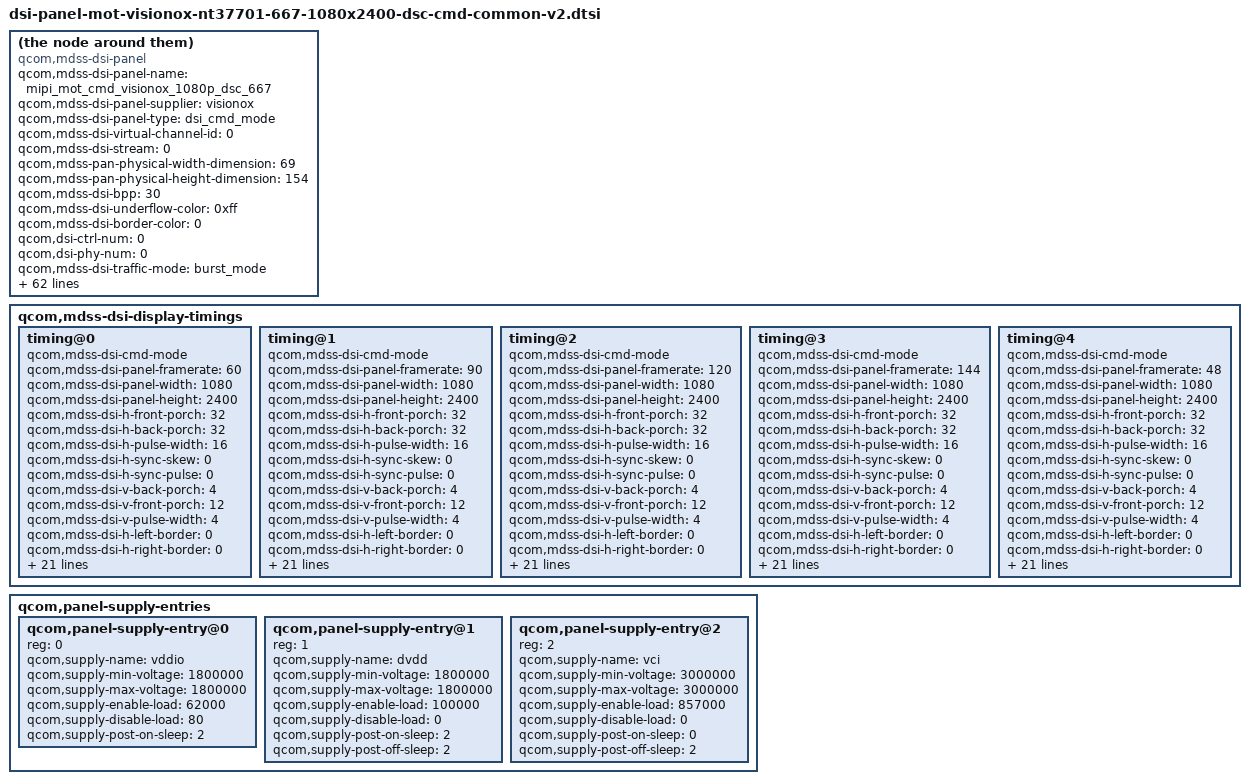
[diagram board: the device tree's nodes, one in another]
/* Copyright (c) 2019-2020, The Linux Foundation. All rights reserved.
 *
 * This program is free software; you can redistribute it and/or modify
 * it under the terms of the GNU General Public License version 2 and
 * only version 2 as published by the Free Software Foundation.
 *
 * This program is distributed in the hope that it will be useful,
 * but WITHOUT ANY WARRANTY; without even the implied warranty of
 * MERCHANTABILITY or FITNESS FOR A PARTICULAR PURPOSE.  See the
 * GNU General Public License for more details.
 */

compatible = "qcom,mdss-dsi-panel";
qcom,mdss-dsi-panel-name = "mipi_mot_cmd_visionox_1080p_dsc_667";
qcom,mdss-dsi-panel-supplier = "visionox";
qcom,mdss-dsi-panel-type = "dsi_cmd_mode";
qcom,mdss-dsi-virtual-channel-id = <0>;
qcom,mdss-dsi-stream = <0>;
qcom,mdss-pan-physical-width-dimension = <69>;
qcom,mdss-pan-physical-height-dimension = <154>;
qcom,mdss-dsi-bpp = <30>;
qcom,mdss-dsi-underflow-color = <0xff>;
qcom,mdss-dsi-border-color = <0>;

qcom,dsi-ctrl-num = <0>;
qcom,dsi-phy-num = <0>;

qcom,mdss-dsi-traffic-mode = "burst_mode";
qcom,mdss-dsi-bllp-eof-power-mode;
qcom,mdss-dsi-bllp-power-mode;
qcom,mdss-dsi-lane-0-state;
qcom,mdss-dsi-lane-1-state;
qcom,mdss-dsi-lane-2-state;
qcom,mdss-dsi-lane-3-state;

qcom,mdss-dsi-dma-trigger = "trigger_sw";
qcom,mdss-dsi-mdp-trigger = "none";
qcom,mdss-dsi-reset-sequence = <0 11>, <1 1>, <0 1>, <1 11>;
qcom,mdss-dsi-lp11-init;
qcom,mdss-dsi-tx-eot-append;
qcom,mdss-dsi-te-pin-select = <1>;
qcom,mdss-dsi-te-dcs-command = <1>;

qcom,mdss-dsi-te-using-te-pin;

//qcom,esd-check-enabled;
qcom,mdss-dsi-panel-status-check-mode = "te_chk_reg_rd";
qcom,mdss-dsi-panel-status-command = [06 01 00 01 00 00 01 0a];
qcom,mdss-dsi-panel-status-command-state = "dsi_lp_mode";
qcom,mdss-dsi-panel-status-value = <0x9c>;
qcom,mdss-dsi-panel-status-read-length = <1>;
//qcom,mdss-dsi-no-panel-on-read-support;

qcom,bklt-dcs-2bytes-enabled;
qcom,mdss-dsi-bl-min-level = <3>;
qcom,mdss-dsi-bl-max-level = <2047>;
qcom,mdss-dsi-bl-default-level = <1024>;
qcom,mdss-brightness-max-level = <2047>;
qcom,mdss-dsi-bl-pmic-control-type = "bl_ctrl_dcs";

qcom,mdss-dsi-hbm-on-command = [
		39 01 00 00 00 00 03 51 0F FF];
qcom,mdss-dsi-hbm-on-command-state = "dsi_lp_mode";
qcom,mdss-dsi-hbm-off-command = [
		39 01 00 00 00 00 03 51 07 FF];
qcom,mdss-dsi-hbm-off-command-state = "dsi_lp_mode";

qcom,mdss-dsi-color-vbt-command = [
                15 01 00 00 00 00 02 55 90];
qcom,mdss-dsi-color-vbt-command-state = "dsi_lp_mode";
qcom,mdss-dsi-color-std-command = [
                15 01 00 00 00 00 02 55 90];
qcom,mdss-dsi-color-std-command-state = "dsi_lp_mode";
qcom,mdss-dsi-color-game-command = [
		15 01 00 00 00 00 02 55 80];
qcom,mdss-dsi-color-game-command-state = "dsi_lp_mode";
qcom,mdss-dsi-color-none-command = [
		15 01 00 00 00 00 02 55 90];
qcom,mdss-dsi-color-none-command-state = "dsi_lp_mode";

qcom,mdss-dsi-dc-on-command = [
		39 01 00 00 00 00 06 F0 55 AA 52 08 00
		15 00 00 00 00 00 02 B2 90
		15 00 00 00 00 00 02 6F 0F
		39 00 00 00 00 00 09 B2 00 30 00 00 00 00 0F FF
		39 00 00 00 00 00 25 B3 00 00 00 00 00 00 00 00 00 00 00 00 00 00 00 00 00 00 00 00 00 00 01 C2 01 C2 03 C0 03 C0 07 FF 07 FF 0F FF
		39 00 00 00 00 00 27 B4 00 0A 00 0A 00 0A 00 0A 00 0A 00 0A 00 0A 00 0A 00 0A 00 0A 00 0A 00 0A 00 0A 00 0A 00 0A 00 0A 00 0A 00 0A 00 0A
		15 00 00 00 00 00 02 6F 2C
		39 00 00 00 00 00 27 B3 00 0A 00 0A 00 0A 00 0A 00 0A 00 0A 00 0A 00 0A 00 0A 00 0A 00 0A 00 0A 00 0A 00 0A 00 0A 00 0A 00 0A 00 0A 00 0A
		15 00 00 00 00 00 02 6F 30
		39 00 00 00 00 00 27 B4 00 0A 00 0A 00 0A 00 0A 00 0A 00 0A 00 0A 00 0A 00 0A 00 0A 00 0A 00 0A 00 0A 00 0A 00 0A 00 0A 00 0A 00 0A 00 0A
		15 00 00 00 00 00 02 6F 56
		39 01 00 00 00 00 27 B4 00 0A 00 0A 00 0A 00 0A 00 0A 00 0A 00 0A 00 0A 00 0A 00 0A 00 0A 00 0A 00 0A 00 0A 00 0A 00 0A 00 0A 00 0A 00 0A

		15 00 00 00 00 00 02 6F AC
		39 00 00 00 00 00 15 B2 00 00 01 40 01 B6 02 0F 02 59 02 99 02 D3 03 07 03 38 03 65
		15 00 00 00 00 00 02 6F C0
		39 00 00 00 00 00 15 B2 03 B8 04 C5 05 98 06 4C 06 EA 07 79 07 FC 08 76 08 E7 09 53
		15 00 00 00 00 00 02 6F D4
		39 00 00 00 00 00 15 B2 09 B9 0A 1A 0A 77 0A D0 0B 26 0B C0 0C 50 0C D9 0D 5B 0D D8
		15 00 00 00 00 00 02 6F E8
		39 00 00 00 00 00 0b B2 0E 50 0E C3 0F 32 0F 9D 0F FF
		15 00 00 00 00 00 02 6F 52
		39 00 00 00 00 00 15 B3 00 01 00 03 00 04 00 06 00 08 00 09 00 0B 00 0D 00 0E 00 12
		15 00 00 00 00 00 02 6F 66
		39 00 00 00 00 00 15 B3 00 1F 00 2C 00 39 00 47 00 54 00 61 00 6E 00 7C 00 89 00 96
		15 00 00 00 00 00 02 6F 7A
		39 00 00 00 00 00 15 B3 00 A3 00 B1 00 BE 00 CB 00 E4 00 FD 01 15 01 2E 01 47 01 60
		15 00 00 00 00 00 02 6F 8E
		39 00 00 00 00 00 09 B3 01 79 01 92 01 AA 01 C2
		39 00 00 00 00 00 06 F0 55 AA 52 08 04
		39 00 00 00 00 00 11 CB 86 02 05 20 4C B8 00 08 00 96 01 C2 03 C0 07 FF
		39 01 00 00 00 00 06 F0 55 AA 52 08 04
		//60HZ
		//R
		15 00 00 00 00 00 02 6F 00
		39 00 00 00 00 00 1a D2 45 4F 2F 1F 1F 36 36 26 26 16 13 40 40 30 20 71 3F 3F 3F 3F 6F 3E 3E 3E 3E
		//G
		15 00 00 00 00 00 02 6F 19
		39 00 00 00 00 00 1a D2 45 4F 2F 1F 1F 36 35 25 25 15 13 40 40 30 20 6F 3E 3E 3E 3E 6D 3D 3D 3D 3D
		//B
		15 00 00 00 00 00 02 6F 32
		39 01 00 00 00 00 1a D2 45 4F 2F 1F 1F 33 36 26 26 16 13 40 40 30 20 70 3E 3E 3E 3E 76 41 3F 31 31
		//120HZ
		//R
		15 00 00 00 00 00 02 6F 00
		39 00 00 00 00 00 1a D4 5F 6F 4F 2F 1F 3F 4F 36 36 26 1F 20 40 30 30 71 3F 3F 3F 3F 6F 3E 3E 3E 3E
		//G
		15 00 00 00 00 00 02 6F 19
		39 00 00 00 00 00 1a D4 5F 6F 4F 2F 1F 3F 4F 35 35 25 1F 20 40 30 30 6F 3E 3E 3E 3E 6D 3D 3D 3D 3D
		//B
		15 00 00 00 00 00 02 6F 32
		39 01 00 00 00 00 1a D4 5F 6F 4F 2F 1F 3F 4F 36 36 26 1F 20 40 30 30 70 3E 3E 3E 3E 76 41 41 41 41
		//144Hz
		//R
		15 00 00 00 00 00 02 6F 00
		39 00 00 00 00 00 1a D9 56 8F 4F 2F 1F 4F 4F 36 36 26 16 50 40 40 20 71 3F 3F 3F 3F 36 3E 3E 3E 3E
		//G
		15 00 00 00 00 00 02 6F 19
		39 00 00 00 00 00 1a D9 56 8F 4F 2F 1F 4F 4F 35 35 25 16 50 40 40 20 6F 3E 3E 3E 3E 36 3D 3D 3D 3D
		//B
		15 01 00 00 00 00 02 6F 32
		39 01 00 00 00 00 1a D9 56 8F 4F 2F 1F 4F 4F 36 36 26 16 50 40 40 20 70 3E 3E 3E 3E 36 41 41 41 41];
qcom,mdss-dsi-dc-on-command-state = "dsi_lp_mode";

qcom,mdss-dsi-dc-off-command = [
		39 01 00 00 00 00 06 F0 55 AA 52 08 00
		15 00 00 00 00 00 02 B2 11
		15 00 00 00 00 00 02 6F 0F
		39 00 00 00 00 00 09 B2 60 30 51 C2 81 C2 0F FF
		39 00 00 00 00 00 25 B3 00 00 00 08 00 08 00 19 00 19 00 32 00 32 00 96 00 96 01 C1 01 C1 01 C2 01 C2 03 C0 03 C0 07 FF 07 FF 0F FF
		//EM_DT_Normal
		39 00 00 00 00 00 27 B4 13 20 13 20 11 10 11 10 11 10 11 10 11 10 11 10 0C E4 0C E4 00 F0 00 F0 00 F0 00 F0 00 F0 00 F0 00 F0 00 F0 00 0A
		//EM_DT_HFR1
		15 00 00 00 00 00 02 6F 2C
		39 00 00 00 00 00 27 B3 0C C0 0C C0 0B 60 0B 60 0B 60 0B 60 0B 60 0B 60 08 98 08 98 00 A0 00 A0 00 A0 00 A0 00 A0 00 A0 00 A0 00 A0 00 0A
		//EM_DT_HFR2
		15 00 00 00 00 00 02 6F 30
		39 00 00 00 00 00 27 B4 09 90 09 90 08 88 08 88 08 88 08 88 08 88 08 88 06 72 06 72 00 78 00 78 00 78 00 78 00 78 00 78 00 78 00 78 00 0A
		//EM_DT_HFR3
		15 00 00 00 00 00 02 6F 56
		39 00 00 00 00 00 27 B4 09 88 09 88 08 7F 08 7F 08 7F 08 7F 08 7F 08 7F 06 6D 06 6D 00 64 00 64 00 64 00 64 00 64 00 64 00 64 00 64 00 0A
		//Demura
		39 00 00 00 00 00 06 F0 55 AA 52 08 04
		39 00 00 00 00 00 11 CB 86 0F 1E 3D 7A B8 00 08 00 96 01 C2 03 C0 07 FF

		39 01 00 00 00 00 06 F0 55 AA 52 08 04
		//60HZ
		//R
		15 00 00 00 00 00 02 6F 00
		39 00 00 00 00 00 1a D2 FF 4F 2F 1F 1F 74 26 26 26 26 73 40 40 40 40 71 3F 3F 3F 3F 6F 3E 3E 3E 3E
		//G
		15 00 00 00 00 00 02 6F 19
		39 00 00 00 00 00 1a D2 FF 4F 2F 1F 1F 86 25 25 25 25 73 40 40 40 40 6F 3E 3E 3E 3E 6D 3D 3D 3D 3D
		//B
		15 00 00 00 00 00 02 6F 32
		39 01 00 00 00 00 1a D2 FF 4F 2F 1F 1F 74 26 26 26 26 73 40 40 40 40 70 3E 3E 3E 3E 76 41 41 41 41
		//120HZ
		//R
		15 00 00 00 00 00 02 6F 00
		39 00 00 00 00 00 1a D4 FF 6F 4F 2F 1F FF 4F 36 36 26 FF 40 40 40 40 71 3F 3F 3F 3F 6F 3E 3E 3E 3E
		//G
		15 00 00 00 00 00 02 6F 19
		39 00 00 00 00 00 1a D4 FF 6F 4F 2F 1F FF 4F 35 35 25 FF 40 40 40 40 6F 3E 3E 3E 3E 6D 3D 3D 3D 3D
		//B
		15 00 00 00 00 00 02 6F 32
		39 01 00 00 00 00 1a D4 FF 6F 4F 2F 1F FF 4F 36 36 26 FF 40 40 40 40 70 3E 3E 3E 3E 76 41 41 41 41
		//144Hz
		//R
		15 00 00 00 00 00 02 6F 00
		39 00 00 00 00 00 1a D9 FF 8F 4F 2F 1F FF 4F 36 36 26 FF 50 40 40 40 71 3F 3F 3F 3F 6F 3E 3E 3E 3E
		//G
		15 00 00 00 00 00 02 6F 19
		39 00 00 00 00 00 1a D9 FF 8F 4F 2F 1F FF 4F 35 35 25 FF 50 40 40 40 6F 3E 3E 3E 3E 6D 3D 3D 3D 3D
		//B
		15 00 00 00 00 00 02 6F 32
		39 01 00 00 00 00 1a D9 FF 8F 4F 2F 1F FF 4F 36 36 26 FF 50 40 40 40 70 3E 3E 3E 3E 76 41 41 41 41];
qcom,mdss-dsi-dc-off-command-state = "dsi_lp_mode";



//qcom,mdss-dsi-acl-on-command = [
//		39 01 00 00 00 00 06 F0 55 AA 52 08 00
//		15 00 00 00 00 00 02 B0 0C
//		15 01 00 00 00 00 02 55 05];
//qcom,mdss-dsi-acl-off-command = [
//		15 01 00 00 00 00 02 55 00];

qcom,mdss-dsi-panel-hbm-is-51cmd;

qcom,mdss-dsi-display-timings {
	timing@0{
		/* 60 FPS */
		qcom,mdss-dsi-cmd-mode;
		qcom,mdss-dsi-panel-framerate = <60>;
		qcom,mdss-dsi-panel-width = <1080>;
		qcom,mdss-dsi-panel-height = <2400>;
		qcom,mdss-dsi-h-front-porch = <32>;
		qcom,mdss-dsi-h-back-porch = <32>;
		qcom,mdss-dsi-h-pulse-width = <16>;
		qcom,mdss-dsi-h-sync-skew = <0>;
		qcom,mdss-dsi-h-sync-pulse = <0>;
		qcom,mdss-dsi-v-back-porch = <4>;
		qcom,mdss-dsi-v-front-porch = <12>;
		qcom,mdss-dsi-v-pulse-width = <4>;
		qcom,mdss-dsi-h-left-border = <0>;
		qcom,mdss-dsi-h-right-border = <0>;
		qcom,mdss-dsi-v-top-border = <0>;
		qcom,mdss-dsi-v-bottom-border = <0>;
		qcom,mdss-dsi-panel-jitter = <0x20 0xa>;
		//qcom,mdss-mdp-transfer-time-us = <15790>;
		//qcom,mdss-dsi-panel-clockrate = <487870000>;
		qcom,mdss-dsi-timing-switch-command = [
			15 01 00 00 10 00 02 2F 01
			15 01 00 00 00 00 02 8B 00
		];
		qcom,mdss-dsi-on-command = [
			39 01 00 00 00 00 06 F0 55 AA 52 08 00
			15 01 00 00 00 00 02 6F 02
			39 01 00 00 00 00 03 EC 81 C2
			39 01 00 00 00 00 06 F0 55 AA 52 08 00
			39 01 00 00 00 00 19 CC 40 54 5A 60 66 6A 6C 6C 68 62 5B 53 4D 48 44 41 40 50 60 70 58 68 74 74
			39 01 00 00 00 00 12 CD 40 40 40 40 40 40 40 40 40 45 49 4C 4B 48 44 41 40
			39 01 00 00 00 00 13 CE 00 40 40 40 40 40 40 40 40 40 40 40 40 40 40 40 40 40
			39 01 00 00 00 00 12 CF 40 40 40 40 40 40 40 40 40 40 40 40 40 40 40 40 40
			39 01 00 00 00 00 07 D0 00 00 FC 74 0C 1D
			39 01 00 00 00 00 2E D1 50 50 50 50 50 50 50 50 50 50 50 50 50 50 50 50 50 50 50 50 50 50 50 50 00 00 00 00 00 00 00 00 00 00 00 00 00 06 0C 03 09 0F 68 88 00
			39 01 00 00 00 00 07 D3 30 52 74 74 50 10
			39 01 00 00 00 00 1A D4 0F 77 74 0F 00 14 0F 18 1F 05 0D 14 03 07 0A A0 75 FA 10 44 12 00 00 80 00
			39 01 00 00 00 00 14 D7 30 40 40 40 40 40 40 40 40 40 40 40 40 40 40 40 40 40 40
			15 01 00 00 00 00 02 55 90
			39 01 00 00 00 00 06 F0 55 AA 52 08 07
			39 01 00 00 00 00 03 c0 01 0f
			39 01 00 00 00 00 06 F0 55 AA 52 08 00
			15 01 00 00 00 00 02 6F 06
			39 01 00 00 00 00 10 B5 4B 1B 00 00 00 44 2D 00 00 00 1B 1B 1B 1B 1B
			39 01 00 00 00 00 05 FF AA 55 A5 80
			15 01 00 00 00 00 02 6F 61
			15 01 00 00 00 00 02 F3 80
			15 01 00 00 00 00 02 03 01
			15 01 00 00 00 00 02 90 01
			39 01 00 00 00 00 13 91 AB 28 00 0C C2 00 03 1C 01 7E 00 0F 08 BB 04 3D 10 F0
			15 01 00 00 00 00 02 2C 00
			15 01 00 00 00 00 02 2F 01
			15 01 00 00 00 00 02 8B 00
			39 01 00 00 00 00 03 51 00 00
			15 01 00 00 00 00 02 53 20
			15 01 00 00 00 00 02 35 00
			39 01 00 00 00 00 05 2A 00 00 04 37
			39 01 00 00 00 00 05 2B 00 00 09 5F
			39 01 00 00 00 00 06 F0 55 AA 52 08 04
			//60HZ
			//R
			15 00 00 00 00 00 02 6F 00
			39 00 00 00 00 00 1a D2 FF 4F 2F 1F 1F 74 26 26 26 26 73 40 40 40 40 71 3F 3F 3F 3F 6F 3E 3E 3E 3E
			//G
			15 00 00 00 00 00 02 6F 19
			39 00 00 00 00 00 1a D2 FF 4F 2F 1F 1F 86 25 25 25 25 73 40 40 40 40 6F 3E 3E 3E 3E 6D 3D 3D 3D 3D
			//B
			15 00 00 00 00 00 02 6F 32
			39 01 00 00 00 00 1a D2 FF 4F 2F 1F 1F 74 26 26 26 26 73 40 40 40 40 70 3E 3E 3E 3E 76 41 41 41 41
			//120HZ
			//R
			15 00 00 00 00 00 02 6F 00
			39 00 00 00 00 00 1a D4 FF 6F 4F 2F 1F FF 4F 36 36 26 FF 40 40 40 40 71 3F 3F 3F 3F 6F 3E 3E 3E 3E
			//G
			15 00 00 00 00 00 02 6F 19
			39 00 00 00 00 00 1a D4 FF 6F 4F 2F 1F FF 4F 35 35 25 FF 40 40 40 40 6F 3E 3E 3E 3E 6D 3D 3D 3D 3D
			//B
			15 00 00 00 00 00 02 6F 32
			39 01 00 00 00 00 1a D4 FF 6F 4F 2F 1F FF 4F 36 36 26 FF 40 40 40 40 70 3E 3E 3E 3E 76 41 41 41 41
			//144Hz
			//R
			15 00 00 00 00 00 02 6F 00
			39 00 00 00 00 00 1a D9 FF 8F 4F 2F 1F FF 4F 36 36 26 FF 50 40 40 40 71 3F 3F 3F 3F 6F 3E 3E 3E 3E
			//G
			15 00 00 00 00 00 02 6F 19
			39 00 00 00 00 00 1a D9 FF 8F 4F 2F 1F FF 4F 35 35 25 FF 50 40 40 40 6F 3E 3E 3E 3E 6D 3D 3D 3D 3D
			//B
			15 00 00 00 00 00 02 6F 32
			39 01 00 00 00 00 1a D9 FF 8F 4F 2F 1F FF 4F 36 36 26 FF 50 40 40 40 70 3E 3E 3E 3E 76 41 41 41 41
			39 01 00 00 00 00 06 F0 55 AA 52 08 00
			39 01 00 00 00 00 07 B3 00 00 00 08 00 08
			39 01 00 00 00 00 06 F0 55 AA 52 08 00
			15 01 00 00 00 00 02 6F 08
			15 01 00 00 00 00 02 C0 50
			15 01 00 00 00 00 02 55 90
			05 01 00 00 78 00 01 11
			05 01 00 00 00 00 01 29];	/* display on */
		qcom,mdss-dsi-off-command = [
			05 01 00 00 00 00 01 28		/* display_off */
			05 01 00 00 78 00 01 10];	/* enter sleep mode */

		qcom,mdss-dsi-on-command-state = "dsi_lp_mode";
		qcom,mdss-dsi-off-command-state = "dsi_lp_mode";
		qcom,mdss-dsi-timing-switch-command-state = "dsi_lp_mode";

		qcom,compression-mode = "dsc";
		qcom,mdss-dsc-version = <0x11>;
		qcom,mdss-dsc-slice-height = <12>;
		qcom,mdss-dsc-slice-width = <1080>;
		qcom,mdss-dsc-slice-per-pkt = <1>;
		qcom,mdss-dsc-bit-per-component = <10>;
		qcom,mdss-dsc-bit-per-pixel = <8>;
		qcom,mdss-dsc-block-prediction-enable;
	};

	timing@1{
		/* 90 FPS */
		qcom,mdss-dsi-cmd-mode;
		qcom,mdss-dsi-panel-framerate = <90>;
		qcom,mdss-dsi-panel-width = <1080>;
		qcom,mdss-dsi-panel-height = <2400>;
		qcom,mdss-dsi-h-front-porch = <32>;
		qcom,mdss-dsi-h-back-porch = <32>;
		qcom,mdss-dsi-h-pulse-width = <16>;
		qcom,mdss-dsi-h-sync-skew = <0>;
		qcom,mdss-dsi-h-sync-pulse = <0>;
		qcom,mdss-dsi-v-back-porch = <4>;
		qcom,mdss-dsi-v-front-porch = <12>;
		qcom,mdss-dsi-v-pulse-width = <4>;
		qcom,mdss-dsi-h-left-border = <0>;
		qcom,mdss-dsi-h-right-border = <0>;
		qcom,mdss-dsi-v-top-border = <0>;
		qcom,mdss-dsi-v-bottom-border = <0>;
		qcom,mdss-dsi-panel-jitter = <0x20 0xa>;
		//qcom,mdss-mdp-transfer-time-us = <10311>;
		//qcom,mdss-dsi-panel-clockrate = <731810000>;
		qcom,mdss-dsi-timing-switch-command = [
			15 01 00 00 0B 00 02 2F 02
			15 01 00 00 00 00 02 8B 00
		];
		qcom,mdss-dsi-on-command = [
			39 01 00 00 00 00 06 F0 55 AA 52 08 00
			15 01 00 00 00 00 02 6F 02
			39 01 00 00 00 00 03 EC 81 C2
			39 01 00 00 00 00 06 F0 55 AA 52 08 00
			39 01 00 00 00 00 19 CC 40 54 5A 60 66 6A 6C 6C 68 62 5B 53 4D 48 44 41 40 50 60 70 58 68 74 74
			39 01 00 00 00 00 12 CD 40 40 40 40 40 40 40 40 40 45 49 4C 4B 48 44 41 40
			39 01 00 00 00 00 13 CE 00 40 40 40 40 40 40 40 40 40 40 40 40 40 40 40 40 40
			39 01 00 00 00 00 12 CF 40 40 40 40 40 40 40 40 40 40 40 40 40 40 40 40 40
			39 01 00 00 00 00 07 D0 00 00 FC 74 0C 1D
			39 01 00 00 00 00 2E D1 50 50 50 50 50 50 50 50 50 50 50 50 50 50 50 50 50 50 50 50 50 50 50 50 00 00 00 00 00 00 00 00 00 00 00 00 00 06 0C 03 09 0F 68 88 00
			39 01 00 00 00 00 07 D3 30 52 74 74 50 10
			39 01 00 00 00 00 1A D4 0F 77 74 0F 00 14 0F 18 1F 05 0D 14 03 07 0A A0 75 FA 10 44 12 00 00 80 00
			39 01 00 00 00 00 14 D7 30 40 40 40 40 40 40 40 40 40 40 40 40 40 40 40 40 40 40
			15 01 00 00 00 00 02 55 90
			39 01 00 00 00 00 06 F0 55 AA 52 08 07
			39 01 00 00 00 00 03 c0 01 0f
			39 01 00 00 00 00 06 F0 55 AA 52 08 00
			15 01 00 00 00 00 02 6F 06
			39 01 00 00 00 00 10 B5 4B 1B 00 00 00 44 2D 00 00 00 1B 1B 1B 1B 1B
			39 01 00 00 00 00 05 FF AA 55 A5 80
			15 01 00 00 00 00 02 6F 61
			15 01 00 00 00 00 02 F3 80
			15 01 00 00 00 00 02 03 01
			15 01 00 00 00 00 02 90 01
			39 01 00 00 00 00 13 91 AB 28 00 0C C2 00 03 1C 01 7E 00 0F 08 BB 04 3D 10 F0
			15 01 00 00 00 00 02 2C 00
			15 01 00 00 00 00 02 2F 02
			15 01 00 00 00 00 02 8B 00
			39 01 00 00 00 00 03 51 00 00
			15 01 00 00 00 00 02 53 20
			15 01 00 00 00 00 02 35 00
			39 01 00 00 00 00 05 2A 00 00 04 37
			39 01 00 00 00 00 05 2B 00 00 09 5F
			39 01 00 00 00 00 06 F0 55 AA 52 08 04
			//60HZ
			//R
			15 00 00 00 00 00 02 6F 00
			39 00 00 00 00 00 1a D2 FF 4F 2F 1F 1F 74 26 26 26 26 73 40 40 40 40 71 3F 3F 3F 3F 6F 3E 3E 3E 3E
			//G
			15 00 00 00 00 00 02 6F 19
			39 00 00 00 00 00 1a D2 FF 4F 2F 1F 1F 86 25 25 25 25 73 40 40 40 40 6F 3E 3E 3E 3E 6D 3D 3D 3D 3D
			//B
			15 00 00 00 00 00 02 6F 32
			39 01 00 00 00 00 1a D2 FF 4F 2F 1F 1F 74 26 26 26 26 73 40 40 40 40 70 3E 3E 3E 3E 76 41 41 41 41
			//120HZ
			//R
			15 00 00 00 00 00 02 6F 00
			39 00 00 00 00 00 1a D4 FF 6F 4F 2F 1F FF 4F 36 36 26 FF 40 40 40 40 71 3F 3F 3F 3F 6F 3E 3E 3E 3E
			//G
			15 00 00 00 00 00 02 6F 19
			39 00 00 00 00 00 1a D4 FF 6F 4F 2F 1F FF 4F 35 35 25 FF 40 40 40 40 6F 3E 3E 3E 3E 6D 3D 3D 3D 3D
			//B
			15 00 00 00 00 00 02 6F 32
			39 01 00 00 00 00 1a D4 FF 6F 4F 2F 1F FF 4F 36 36 26 FF 40 40 40 40 70 3E 3E 3E 3E 76 41 41 41 41
			//144Hz
			//R
			15 00 00 00 00 00 02 6F 00
			39 00 00 00 00 00 1a D9 FF 8F 4F 2F 1F FF 4F 36 36 26 FF 50 40 40 40 71 3F 3F 3F 3F 6F 3E 3E 3E 3E
			//G
			15 00 00 00 00 00 02 6F 19
			39 00 00 00 00 00 1a D9 FF 8F 4F 2F 1F FF 4F 35 35 25 FF 50 40 40 40 6F 3E 3E 3E 3E 6D 3D 3D 3D 3D
			//B
			15 00 00 00 00 00 02 6F 32
			39 01 00 00 00 00 1a D9 FF 8F 4F 2F 1F FF 4F 36 36 26 FF 50 40 40 40 70 3E 3E 3E 3E 76 41 41 41 41
			39 01 00 00 00 00 06 F0 55 AA 52 08 00
			39 01 00 00 00 00 07 B3 00 00 00 08 00 08
			39 01 00 00 00 00 06 F0 55 AA 52 08 00
			15 01 00 00 00 00 02 6F 08
			15 01 00 00 00 00 02 C0 50
			15 01 00 00 00 00 02 55 90
			05 01 00 00 78 00 01 11
			05 01 00 00 00 00 01 29];	/* display on */
		qcom,mdss-dsi-off-command = [
			05 01 00 00 00 00 01 28		/* display_off */
			05 01 00 00 78 00 01 10];	/* enter sleep mode */

		qcom,mdss-dsi-on-command-state = "dsi_lp_mode";
		qcom,mdss-dsi-off-command-state = "dsi_lp_mode";
		qcom,mdss-dsi-timing-switch-command-state = "dsi_lp_mode";

		qcom,compression-mode = "dsc";
		qcom,mdss-dsc-version = <0x11>;
		qcom,mdss-dsc-slice-height = <12>;
		qcom,mdss-dsc-slice-width = <1080>;
		qcom,mdss-dsc-slice-per-pkt = <1>;
		qcom,mdss-dsc-bit-per-component = <10>;
		qcom,mdss-dsc-bit-per-pixel = <8>;
		qcom,mdss-dsc-block-prediction-enable;
	};

	timing@2{
		/* 120 FPS */
		qcom,mdss-dsi-cmd-mode;
		qcom,mdss-dsi-panel-framerate = <120>;
		qcom,mdss-dsi-panel-width = <1080>;
		qcom,mdss-dsi-panel-height = <2400>;
		qcom,mdss-dsi-h-front-porch = <32>;
		qcom,mdss-dsi-h-back-porch = <32>;
		qcom,mdss-dsi-h-pulse-width = <16>;
		qcom,mdss-dsi-h-sync-skew = <0>;
		qcom,mdss-dsi-h-sync-pulse = <0>;
		qcom,mdss-dsi-v-back-porch = <4>;
		qcom,mdss-dsi-v-front-porch = <12>;
		qcom,mdss-dsi-v-pulse-width = <4>;
		qcom,mdss-dsi-h-left-border = <0>;
		qcom,mdss-dsi-h-right-border = <0>;
		qcom,mdss-dsi-v-top-border = <0>;
		qcom,mdss-dsi-v-bottom-border = <0>;
		qcom,mdss-dsi-panel-jitter = <0x20 0xa>;
		//qcom,mdss-mdp-transfer-time-us = <7533>;
		//qcom,mdss-dsi-panel-clockrate = <975740000>;
		qcom,mdss-dsi-timing-switch-command = [
			15 01 00 00 08 00 02 2F 03
			15 01 00 00 00 00 02 8B 00
		];
		qcom,mdss-dsi-on-command = [
			39 01 00 00 00 00 06 F0 55 AA 52 08 00
			15 01 00 00 00 00 02 6F 02
			39 01 00 00 00 00 03 EC 81 C2
			39 01 00 00 00 00 06 F0 55 AA 52 08 00
			39 01 00 00 00 00 19 CC 40 54 5A 60 66 6A 6C 6C 68 62 5B 53 4D 48 44 41 40 50 60 70 58 68 74 74
			39 01 00 00 00 00 12 CD 40 40 40 40 40 40 40 40 40 45 49 4C 4B 48 44 41 40
			39 01 00 00 00 00 13 CE 00 40 40 40 40 40 40 40 40 40 40 40 40 40 40 40 40 40
			39 01 00 00 00 00 12 CF 40 40 40 40 40 40 40 40 40 40 40 40 40 40 40 40 40
			39 01 00 00 00 00 07 D0 00 00 FC 74 0C 1D
			39 01 00 00 00 00 2E D1 50 50 50 50 50 50 50 50 50 50 50 50 50 50 50 50 50 50 50 50 50 50 50 50 00 00 00 00 00 00 00 00 00 00 00 00 00 06 0C 03 09 0F 68 88 00
			39 01 00 00 00 00 07 D3 30 52 74 74 50 10
			39 01 00 00 00 00 1A D4 0F 77 74 0F 00 14 0F 18 1F 05 0D 14 03 07 0A A0 75 FA 10 44 12 00 00 80 00
			39 01 00 00 00 00 14 D7 30 40 40 40 40 40 40 40 40 40 40 40 40 40 40 40 40 40 40
			15 01 00 00 00 00 02 55 90
			39 01 00 00 00 00 06 F0 55 AA 52 08 07
			39 01 00 00 00 00 03 c0 01 0f
			39 01 00 00 00 00 06 F0 55 AA 52 08 00
			15 01 00 00 00 00 02 6F 06
			39 01 00 00 00 00 10 B5 4B 1B 00 00 00 44 2D 00 00 00 1B 1B 1B 1B 1B
			39 01 00 00 00 00 05 FF AA 55 A5 80
			15 01 00 00 00 00 02 6F 61
			15 01 00 00 00 00 02 F3 80
			15 01 00 00 00 00 02 03 01
			15 01 00 00 00 00 02 90 01
			39 01 00 00 00 00 13 91 AB 28 00 0C C2 00 03 1C 01 7E 00 0F 08 BB 04 3D 10 F0
			15 01 00 00 00 00 02 2C 00
			15 01 00 00 00 00 02 2F 03
			15 01 00 00 00 00 02 8B 00
			39 01 00 00 00 00 03 51 00 00
			15 01 00 00 00 00 02 53 20
			15 01 00 00 00 00 02 35 00
			39 01 00 00 00 00 05 2A 00 00 04 37
			39 01 00 00 00 00 05 2B 00 00 09 5F
			39 01 00 00 00 00 06 F0 55 AA 52 08 04
			//60HZ
			//R
			15 00 00 00 00 00 02 6F 00
			39 00 00 00 00 00 1a D2 FF 4F 2F 1F 1F 74 26 26 26 26 73 40 40 40 40 71 3F 3F 3F 3F 6F 3E 3E 3E 3E
			//G
			15 00 00 00 00 00 02 6F 19
			39 00 00 00 00 00 1a D2 FF 4F 2F 1F 1F 86 25 25 25 25 73 40 40 40 40 6F 3E 3E 3E 3E 6D 3D 3D 3D 3D
			//B
			15 00 00 00 00 00 02 6F 32
			39 01 00 00 00 00 1a D2 FF 4F 2F 1F 1F 74 26 26 26 26 73 40 40 40 40 70 3E 3E 3E 3E 76 41 41 41 41
			//120HZ
			//R
			15 00 00 00 00 00 02 6F 00
			39 00 00 00 00 00 1a D4 FF 6F 4F 2F 1F FF 4F 36 36 26 FF 40 40 40 40 71 3F 3F 3F 3F 6F 3E 3E 3E 3E
			//G
			15 00 00 00 00 00 02 6F 19
			39 00 00 00 00 00 1a D4 FF 6F 4F 2F 1F FF 4F 35 35 25 FF 40 40 40 40 6F 3E 3E 3E 3E 6D 3D 3D 3D 3D
			//B
			15 00 00 00 00 00 02 6F 32
			39 01 00 00 00 00 1a D4 FF 6F 4F 2F 1F FF 4F 36 36 26 FF 40 40 40 40 70 3E 3E 3E 3E 76 41 41 41 41
			//144Hz
			//R
			15 00 00 00 00 00 02 6F 00
			39 00 00 00 00 00 1a D9 FF 8F 4F 2F 1F FF 4F 36 36 26 FF 50 40 40 40 71 3F 3F 3F 3F 6F 3E 3E 3E 3E
			//G
			15 00 00 00 00 00 02 6F 19
			39 00 00 00 00 00 1a D9 FF 8F 4F 2F 1F FF 4F 35 35 25 FF 50 40 40 40 6F 3E 3E 3E 3E 6D 3D 3D 3D 3D
			//B
			15 00 00 00 00 00 02 6F 32
			39 01 00 00 00 00 1a D9 FF 8F 4F 2F 1F FF 4F 36 36 26 FF 50 40 40 40 70 3E 3E 3E 3E 76 41 41 41 41
                        39 01 00 00 00 00 06 F0 55 AA 52 08 00
                        39 01 00 00 00 00 07 B3 00 00 00 08 00 08
			39 01 00 00 00 00 06 F0 55 AA 52 08 00
			15 01 00 00 00 00 02 6F 08
			15 01 00 00 00 00 02 C0 50
			15 01 00 00 00 00 02 55 90
			05 01 00 00 78 00 01 11
			05 01 00 00 00 00 01 29];	/* display on */
		qcom,mdss-dsi-off-command = [
			05 01 00 00 00 00 01 28		/* display_off */
			05 01 00 00 78 00 01 10];	/* enter sleep mode */

		qcom,mdss-dsi-on-command-state = "dsi_lp_mode";
		qcom,mdss-dsi-off-command-state = "dsi_lp_mode";
		qcom,mdss-dsi-timing-switch-command-state = "dsi_lp_mode";

		qcom,compression-mode = "dsc";
		qcom,mdss-dsc-version = <0x11>;
		qcom,mdss-dsc-slice-height = <12>;
		qcom,mdss-dsc-slice-width = <1080>;
		qcom,mdss-dsc-slice-per-pkt = <1>;
		qcom,mdss-dsc-bit-per-component = <10>;
		qcom,mdss-dsc-bit-per-pixel = <8>;
		qcom,mdss-dsc-block-prediction-enable;
	};

	timing@3{
		/* 144 FPS */
		qcom,mdss-dsi-cmd-mode;
		qcom,mdss-dsi-panel-framerate = <144>;
		qcom,mdss-dsi-panel-width = <1080>;
		qcom,mdss-dsi-panel-height = <2400>;
		qcom,mdss-dsi-h-front-porch = <32>;
		qcom,mdss-dsi-h-back-porch = <32>;
		qcom,mdss-dsi-h-pulse-width = <16>;
		qcom,mdss-dsi-h-sync-skew = <0>;
		qcom,mdss-dsi-h-sync-pulse = <0>;
		qcom,mdss-dsi-v-back-porch = <4>;
		qcom,mdss-dsi-v-front-porch = <12>;
		qcom,mdss-dsi-v-pulse-width = <4>;
		qcom,mdss-dsi-h-left-border = <0>;
		qcom,mdss-dsi-h-right-border = <0>;
		qcom,mdss-dsi-v-top-border = <0>;
		qcom,mdss-dsi-v-bottom-border = <0>;
		qcom,mdss-dsi-panel-jitter = <0x20 0xa>;
		//qcom,mdss-mdp-transfer-time-us = <6144>;
		//qcom,mdss-dsi-panel-clockrate = <1170890000>;
		qcom,mdss-dsi-timing-switch-command = [
			15 01 00 00 06 00 02 2F 04
			15 01 00 00 00 00 02 8B 10
		];
		qcom,mdss-dsi-on-command = [
			39 01 00 00 00 00 06 F0 55 AA 52 08 00
			15 01 00 00 00 00 02 6F 02
			39 01 00 00 00 00 03 EC 81 C2
			39 01 00 00 00 00 06 F0 55 AA 52 08 00
			39 01 00 00 00 00 19 CC 40 54 5A 60 66 6A 6C 6C 68 62 5B 53 4D 48 44 41 40 50 60 70 58 68 74 74
			39 01 00 00 00 00 12 CD 40 40 40 40 40 40 40 40 40 45 49 4C 4B 48 44 41 40
			39 01 00 00 00 00 13 CE 00 40 40 40 40 40 40 40 40 40 40 40 40 40 40 40 40 40
			39 01 00 00 00 00 12 CF 40 40 40 40 40 40 40 40 40 40 40 40 40 40 40 40 40
			39 01 00 00 00 00 07 D0 00 00 FC 74 0C 1D
			39 01 00 00 00 00 2E D1 50 50 50 50 50 50 50 50 50 50 50 50 50 50 50 50 50 50 50 50 50 50 50 50 00 00 00 00 00 00 00 00 00 00 00 00 00 06 0C 03 09 0F 68 88 00
			39 01 00 00 00 00 07 D3 30 52 74 74 50 10
			39 01 00 00 00 00 1A D4 0F 77 74 0F 00 14 0F 18 1F 05 0D 14 03 07 0A A0 75 FA 10 44 12 00 00 80 00
			39 01 00 00 00 00 14 D7 30 40 40 40 40 40 40 40 40 40 40 40 40 40 40 40 40 40 40
			15 01 00 00 00 00 02 55 90
			39 01 00 00 00 00 06 F0 55 AA 52 08 07
			39 01 00 00 00 00 03 c0 01 0f
			39 01 00 00 00 00 06 F0 55 AA 52 08 00
			15 01 00 00 00 00 02 6F 06
			39 01 00 00 00 00 10 B5 4B 1B 00 00 00 44 2D 00 00 00 1B 1B 1B 1B 1B
			39 01 00 00 00 00 05 FF AA 55 A5 80
			15 01 00 00 00 00 02 6F 61
			15 01 00 00 00 00 02 F3 80
			15 01 00 00 00 00 02 03 01
			15 01 00 00 00 00 02 90 01
			39 01 00 00 00 00 13 91 AB 28 00 0C C2 00 03 1C 01 7E 00 0F 08 BB 04 3D 10 F0
			15 01 00 00 00 00 02 2C 00
			15 01 00 00 00 00 02 2F 04
			15 01 00 00 00 00 02 8B 10
			39 01 00 00 00 00 03 51 00 00
			15 01 00 00 00 00 02 53 20
			15 01 00 00 00 00 02 35 00
			39 01 00 00 00 00 05 2A 00 00 04 37
			39 01 00 00 00 00 05 2B 00 00 09 5F
			39 01 00 00 00 00 06 F0 55 AA 52 08 04
			//60HZ
			//R
			15 00 00 00 00 00 02 6F 00
			39 00 00 00 00 00 1a D2 FF 4F 2F 1F 1F 74 26 26 26 26 73 40 40 40 40 71 3F 3F 3F 3F 6F 3E 3E 3E 3E
			//G
			15 00 00 00 00 00 02 6F 19
			39 00 00 00 00 00 1a D2 FF 4F 2F 1F 1F 86 25 25 25 25 73 40 40 40 40 6F 3E 3E 3E 3E 6D 3D 3D 3D 3D
			//B
			15 00 00 00 00 00 02 6F 32
			39 01 00 00 00 00 1a D2 FF 4F 2F 1F 1F 74 26 26 26 26 73 40 40 40 40 70 3E 3E 3E 3E 76 41 41 41 41
			//120HZ
			//R
			15 00 00 00 00 00 02 6F 00
			39 00 00 00 00 00 1a D4 FF 6F 4F 2F 1F FF 4F 36 36 26 FF 40 40 40 40 71 3F 3F 3F 3F 6F 3E 3E 3E 3E
			//G
			15 00 00 00 00 00 02 6F 19
			39 00 00 00 00 00 1a D4 FF 6F 4F 2F 1F FF 4F 35 35 25 FF 40 40 40 40 6F 3E 3E 3E 3E 6D 3D 3D 3D 3D
			//B
			15 00 00 00 00 00 02 6F 32
			39 01 00 00 00 00 1a D4 FF 6F 4F 2F 1F FF 4F 36 36 26 FF 40 40 40 40 70 3E 3E 3E 3E 76 41 41 41 41
			//144Hz
			//R
			15 00 00 00 00 00 02 6F 00
			39 00 00 00 00 00 1a D9 FF 8F 4F 2F 1F FF 4F 36 36 26 FF 50 40 40 40 71 3F 3F 3F 3F 6F 3E 3E 3E 3E
			//G
			15 00 00 00 00 00 02 6F 19
			39 00 00 00 00 00 1a D9 FF 8F 4F 2F 1F FF 4F 35 35 25 FF 50 40 40 40 6F 3E 3E 3E 3E 6D 3D 3D 3D 3D
			//B
			15 00 00 00 00 00 02 6F 32
			39 01 00 00 00 00 1a D9 FF 8F 4F 2F 1F FF 4F 36 36 26 FF 50 40 40 40 70 3E 3E 3E 3E 76 41 41 41 41
			39 01 00 00 00 00 06 F0 55 AA 52 08 00
			39 01 00 00 00 00 07 B3 00 00 00 08 00 08
			39 01 00 00 00 00 06 F0 55 AA 52 08 00
			15 01 00 00 00 00 02 6F 08
			15 01 00 00 00 00 02 C0 50
			15 01 00 00 00 00 02 55 90
			05 01 00 00 78 00 01 11
			05 01 00 00 00 00 01 29];	/* display on */
		qcom,mdss-dsi-off-command = [
			05 01 00 00 00 00 01 28		/* display_off */
			05 01 00 00 78 00 01 10];	/* enter sleep mode */

		qcom,mdss-dsi-on-command-state = "dsi_lp_mode";
		qcom,mdss-dsi-off-command-state = "dsi_lp_mode";
		qcom,mdss-dsi-timing-switch-command-state = "dsi_lp_mode";

		qcom,compression-mode = "dsc";
		qcom,mdss-dsc-version = <0x11>;
		qcom,mdss-dsc-slice-height = <12>;
		qcom,mdss-dsc-slice-width = <1080>;
		qcom,mdss-dsc-slice-per-pkt = <1>;
		qcom,mdss-dsc-bit-per-component = <10>;
		qcom,mdss-dsc-bit-per-pixel = <8>;
		qcom,mdss-dsc-block-prediction-enable;
	};

	timing@4{
		/* 48 FPS */
		qcom,mdss-dsi-cmd-mode;
		qcom,mdss-dsi-panel-framerate = <48>;
		qcom,mdss-dsi-panel-width = <1080>;
		qcom,mdss-dsi-panel-height = <2400>;
		qcom,mdss-dsi-h-front-porch = <32>;
		qcom,mdss-dsi-h-back-porch = <32>;
		qcom,mdss-dsi-h-pulse-width = <16>;
		qcom,mdss-dsi-h-sync-skew = <0>;
		qcom,mdss-dsi-h-sync-pulse = <0>;
		qcom,mdss-dsi-v-back-porch = <4>;
		qcom,mdss-dsi-v-front-porch = <12>;
		qcom,mdss-dsi-v-pulse-width = <4>;
		qcom,mdss-dsi-h-left-border = <0>;
		qcom,mdss-dsi-h-right-border = <0>;
		qcom,mdss-dsi-v-top-border = <0>;
		qcom,mdss-dsi-v-bottom-border = <0>;
		qcom,mdss-dsi-panel-jitter = <0x20 0xa>;
		//qcom,mdss-mdp-transfer-time-us = <19824>;
		//qcom,mdss-dsi-panel-clockrate = <390300000>;
		qcom,mdss-dsi-timing-switch-command = [
			15 01 00 00 14 00 02 2F 07
			15 01 00 00 00 00 02 8B 00
		];
		qcom,mdss-dsi-on-command = [
			39 01 00 00 00 00 06 F0 55 AA 52 08 00
			15 01 00 00 00 00 02 6F 02
			39 01 00 00 00 00 03 EC 81 C2
			39 01 00 00 00 00 06 F0 55 AA 52 08 00
			39 01 00 00 00 00 19 CC 40 54 5A 60 66 6A 6C 6C 68 62 5B 53 4D 48 44 41 40 50 60 70 58 68 74 74
			39 01 00 00 00 00 12 CD 40 40 40 40 40 40 40 40 40 45 49 4C 4B 48 44 41 40
			39 01 00 00 00 00 13 CE 00 40 40 40 40 40 40 40 40 40 40 40 40 40 40 40 40 40
			39 01 00 00 00 00 12 CF 40 40 40 40 40 40 40 40 40 40 40 40 40 40 40 40 40
			39 01 00 00 00 00 07 D0 00 00 FC 74 0C 1D
			39 01 00 00 00 00 2E D1 50 50 50 50 50 50 50 50 50 50 50 50 50 50 50 50 50 50 50 50 50 50 50 50 00 00 00 00 00 00 00 00 00 00 00 00 00 06 0C 03 09 0F 68 88 00
			39 01 00 00 00 00 07 D3 30 52 74 74 50 10
			39 01 00 00 00 00 1A D4 0F 77 74 0F 00 14 0F 18 1F 05 0D 14 03 07 0A A0 75 FA 10 44 12 00 00 80 00
			39 01 00 00 00 00 14 D7 30 40 40 40 40 40 40 40 40 40 40 40 40 40 40 40 40 40 40
			15 01 00 00 00 00 02 55 90
			39 01 00 00 00 00 06 F0 55 AA 52 08 07
			39 01 00 00 00 00 03 c0 01 0f
			39 01 00 00 00 00 06 F0 55 AA 52 08 00
			15 01 00 00 00 00 02 6F 06
			39 01 00 00 00 00 10 B5 4B 1B 00 00 00 44 2D 00 00 00 1B 1B 1B 1B 1B
			39 01 00 00 00 00 05 FF AA 55 A5 80
			15 01 00 00 00 00 02 6F 61
			15 01 00 00 00 00 02 F3 80
			15 01 00 00 00 00 02 03 01
			15 01 00 00 00 00 02 90 01
			39 01 00 00 00 00 13 91 AB 28 00 0C C2 00 03 1C 01 7E 00 0F 08 BB 04 3D 10 F0
			15 01 00 00 00 00 02 2C 00
			15 01 00 00 00 00 02 2F 07
			15 01 00 00 00 00 02 8B 00
			39 01 00 00 00 00 03 51 00 00
			15 01 00 00 00 00 02 53 20
			15 01 00 00 00 00 02 35 00
			39 01 00 00 00 00 05 2A 00 00 04 37
			39 01 00 00 00 00 05 2B 00 00 09 5F
			39 01 00 00 00 00 06 F0 55 AA 52 08 04
			//60HZ
			//R
			15 00 00 00 00 00 02 6F 00
			39 00 00 00 00 00 1a D2 FF 4F 2F 1F 1F 74 26 26 26 26 73 40 40 40 40 71 3F 3F 3F 3F 6F 3E 3E 3E 3E
			//G
			15 00 00 00 00 00 02 6F 19
			39 00 00 00 00 00 1a D2 FF 4F 2F 1F 1F 86 25 25 25 25 73 40 40 40 40 6F 3E 3E 3E 3E 6D 3D 3D 3D 3D
			//B
			15 00 00 00 00 00 02 6F 32
			39 01 00 00 00 00 1a D2 FF 4F 2F 1F 1F 74 26 26 26 26 73 40 40 40 40 70 3E 3E 3E 3E 76 41 41 41 41
			//120HZ
			//R
			15 00 00 00 00 00 02 6F 00
			39 00 00 00 00 00 1a D4 FF 6F 4F 2F 1F FF 4F 36 36 26 FF 40 40 40 40 71 3F 3F 3F 3F 6F 3E 3E 3E 3E
			//G
			15 00 00 00 00 00 02 6F 19
			39 00 00 00 00 00 1a D4 FF 6F 4F 2F 1F FF 4F 35 35 25 FF 40 40 40 40 6F 3E 3E 3E 3E 6D 3D 3D 3D 3D
			//B
			15 00 00 00 00 00 02 6F 32
			39 01 00 00 00 00 1a D4 FF 6F 4F 2F 1F FF 4F 36 36 26 FF 40 40 40 40 70 3E 3E 3E 3E 76 41 41 41 41
			//144Hz
			//R
			15 00 00 00 00 00 02 6F 00
			39 00 00 00 00 00 1a D9 FF 8F 4F 2F 1F FF 4F 36 36 26 FF 50 40 40 40 71 3F 3F 3F 3F 6F 3E 3E 3E 3E
			//G
			15 00 00 00 00 00 02 6F 19
			39 00 00 00 00 00 1a D9 FF 8F 4F 2F 1F FF 4F 35 35 25 FF 50 40 40 40 6F 3E 3E 3E 3E 6D 3D 3D 3D 3D
			//B
			15 00 00 00 00 00 02 6F 32
			39 01 00 00 00 00 1a D9 FF 8F 4F 2F 1F FF 4F 36 36 26 FF 50 40 40 40 70 3E 3E 3E 3E 76 41 41 41 41
			39 01 00 00 00 00 06 F0 55 AA 52 08 00
			39 01 00 00 00 00 07 B3 00 00 00 08 00 08
			39 01 00 00 00 00 06 F0 55 AA 52 08 00
			15 01 00 00 00 00 02 6F 08
			15 01 00 00 00 00 02 C0 50
			15 01 00 00 00 00 02 55 90
			05 01 00 00 78 00 01 11
			05 01 00 00 00 00 01 29];	/* display on */
		qcom,mdss-dsi-off-command = [
			05 01 00 00 00 00 01 28		/* display_off */
			05 01 00 00 78 00 01 10];	/* enter sleep mode */

		qcom,mdss-dsi-on-command-state = "dsi_lp_mode";
		qcom,mdss-dsi-off-command-state = "dsi_lp_mode";
		qcom,mdss-dsi-timing-switch-command-state = "dsi_lp_mode";

		qcom,compression-mode = "dsc";
		qcom,mdss-dsc-version = <0x11>;
		qcom,mdss-dsc-slice-height = <12>;
		qcom,mdss-dsc-slice-width = <1080>;
		qcom,mdss-dsc-slice-per-pkt = <1>;
		qcom,mdss-dsc-bit-per-component = <10>;
		qcom,mdss-dsc-bit-per-pixel = <8>;
		qcom,mdss-dsc-block-prediction-enable;
	};
};

qcom,panel-supply-entries {
	#address-cells = <1>;
	#size-cells = <0>;

	qcom,panel-supply-entry@0 {
		reg = <0>;
		qcom,supply-name = "vddio";
		qcom,supply-min-voltage = <1800000>;
		qcom,supply-max-voltage = <1800000>;
		qcom,supply-enable-load = <62000>;
		qcom,supply-disable-load = <80>;
		qcom,supply-post-on-sleep = <2>;
	};

	qcom,panel-supply-entry@1 {
		reg = <1>;
		qcom,supply-name = "dvdd";
		qcom,supply-min-voltage = <1800000>;
		qcom,supply-max-voltage = <1800000>;
		qcom,supply-enable-load = <100000>;
		qcom,supply-disable-load = <0>;
		qcom,supply-post-on-sleep = <2>;
		qcom,supply-post-off-sleep = <2>;
	};

	qcom,panel-supply-entry@2 {
		reg = <2>;
		qcom,supply-name = "vci";
		qcom,supply-min-voltage = <3000000>;
		qcom,supply-max-voltage = <3000000>;
		qcom,supply-enable-load = <857000>;
		qcom,supply-disable-load = <0>;
		qcom,supply-post-on-sleep = <0>;
		qcom,supply-post-off-sleep = <2>;
	};
};
